# AT32F457xx_v2 register map
Vendor: Keil; Series: AT32F457; File version: 1.0
CPU: CM4 r0p1, little endian, no MPU, FPU, 4 interrupt priority bits
Registers are 32-bit, read-write, reset 0x0 unless marked. A register's access mark holds for its fields unless they carry their own. Offsets are from the block's base; [hi:lo] are bit positions; {n}, {i} and the like mark numbered series.

## CRM — Clock and reset management
Base 0x40023800
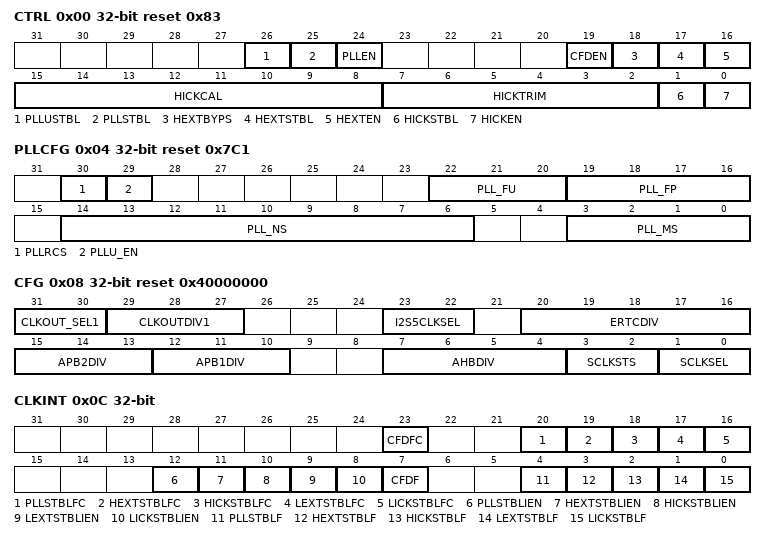
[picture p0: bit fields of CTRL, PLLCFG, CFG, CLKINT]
0x00 CTRL reset 0x83 — Clock control register
  [26] PLLUSTBL ro — PLLU clock ready flag
  [25] PLLSTBL ro — PLL clock ready flag
  [24] PLLEN — PLL enable
  [19] CFDEN — Clock failure detection enable
  [18] HEXTBYPS — High speed exernal crystal bypass
  [17] HEXTSTBL ro — High speed exernal crystal ready flag
  [16] HEXTEN — High speed exernal crystal enable
  [15:8] HICKCAL ro — High speed internal clock calibration
  [7:2] HICKTRIM — High speed internal clock trimming
  [1] HICKSTBL ro — High speed internal clock ready flag
  [0] HICKEN — High speed internal clock enable
0x04 PLLCFG reset 0x7C1 — PLL configuration register (CRM_PLLCFG)
  [30] PLLRCS — PLL reference clock select
  [29] PLLU_EN — PLLU enable
  [22:20] PLL_FU — PLLU post-division
  [19:16] PLL_FP — PLLP post-division
  [14:6] PLL_NS — PLL frequency multiplication factor
  [3:0] PLL_MS — PLL pre-division
0x08 CFG reset 0x40000000 — Clock configuration register(CRM_CFG)
  [31:30] CLKOUT_SEL1 — Clock output selection1
  [29:27] CLKOUTDIV1 — Clock output division1
  [23:22] I2S5CLKSEL — I2S clock select
  [20:16] ERTCDIV — HEXT division for ERTC clock
  [15:13] APB2DIV — APB2 division
  [12:10] APB1DIV — APB1 division
  [7:4] AHBDIV — AHB division
  [3:2] SCLKSTS ro — System Clock select Status
  [1:0] SCLKSEL — System clock select
0x0C CLKINT — Clock interrupt register (CRM_CLKINT)
  [23] CFDFC wo — Clock failure detection interrupt clear
  [20] PLLSTBLFC wo — PLL ready interrupt clear
  [19] HEXTSTBLFC wo — HEXT ready interrupt clear
  [18] HICKSTBLFC wo — HICK ready interrupt clear
  [17] LEXTSTBLFC wo — LEXT ready interrupt clear
  [16] LICKSTBLFC wo — LICK ready interrupt clear
  [12] PLLSTBLIEN — PLL ready interrupt enable
  [11] HEXTSTBLIEN — HEXT ready interrupt enable
  [10] HICKSTBLIEN — HICK ready interrupt enable
  [9] LEXTSTBLIEN — LEXT ready interrupt enable
  [8] LICKSTBLIEN — LICK ready interrupt enable
  [7] CFDF ro — Clock failure detection interrupt flag
  [4] PLLSTBLF ro — PLL ready interrupt flag
  [3] HEXTSTBLF ro — HEXT ready interrupt flag
  [2] HICKSTBLF ro — HICK ready interrupt flag
  [1] LEXTSTBLF ro — LEXT ready interrupt flag
  [0] LICKSTBLF ro — LICK ready interrupt flag
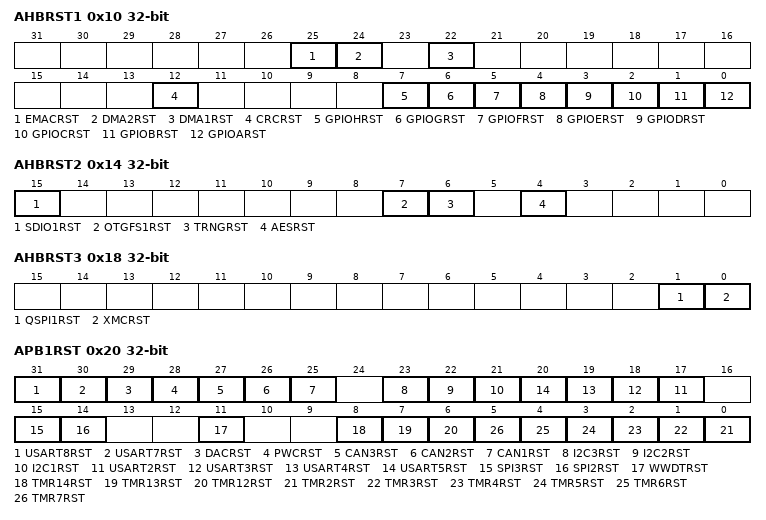
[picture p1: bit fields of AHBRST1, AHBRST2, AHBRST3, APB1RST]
0x10 AHBRST1 — AHB peripheral reset register1 (CRM_AHBRST1)
  [25] EMACRST — EMAC interface reset
  [24] DMA2RST — DMA2 reset
  [22] DMA1RST — DMA1 reset
  [12] CRCRST — CRC reset
  [7] GPIOHRST — IO port H reset
  [6] GPIOGRST — IO port G reset
  [5] GPIOFRST — IO port F reset
  [4] GPIOERST — IO port E reset
  [3] GPIODRST — IO port D reset
  [2] GPIOCRST — IO port C reset
  [1] GPIOBRST — IO port B reset
  [0] GPIOARST — IO port A reset
0x14 AHBRST2 — AHB peripheral reset register 2 (CRM_AHBRST2)
  [15] SDIO1RST — SDIO1 reset
  [7] OTGFS1RST — OTGFS1 reset
  [6] TRNGRST — TRNG reset
  [4] AESRST — AES reset
0x18 AHBRST3 — AHB peripheral reset register 3 (CRM_AHBRST3)
  [1] QSPI1RST — QSPI1 reset
  [0] XMCRST — XMC reset
0x20 APB1RST — APB1 peripheral reset register (CRM_APB1RST)
  [31] USART8RST — USART8 reset
  [30] USART7RST — USART7 reset
  [29] DACRST — DAC reset
  [28] PWCRST — PWC reset
  [27] CAN3RST — CAN3 reset
  [26] CAN2RST — CAN2 reset
  [25] CAN1RST — CAN1 reset
  [23] I2C3RST — I2C3 reset
  [22] I2C2RST — I2C2 reset
  [21] I2C1RST — I2C1 reset
  [n+15] USART{n}RST (n=2..5) — USART{n} reset
  [15] SPI3RST — SPI3 reset
  [14] SPI2RST — SPI2 reset
  [11] WWDTRST — Window watchdog reset
  [8] TMR14RST — Timer14 reset
  [7] TMR13RST — Timer13 reset
  [6] TMR12RST — Timer12 reset
  [n-2] TMR{n}RST (n=2..7) — Timer{n} reset
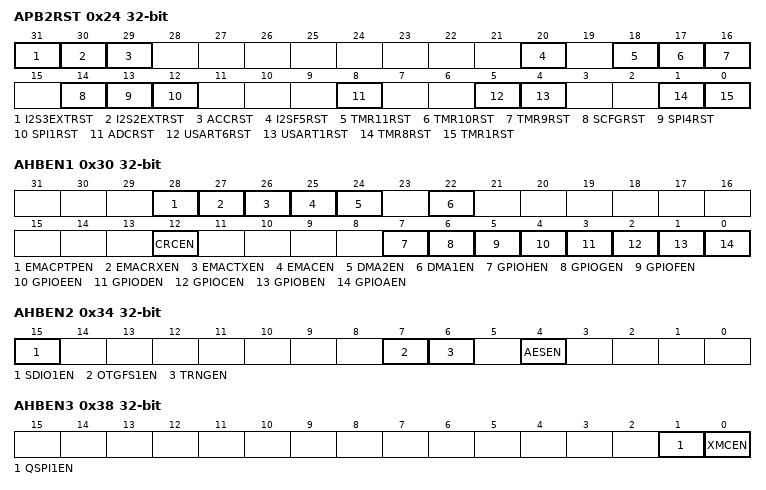
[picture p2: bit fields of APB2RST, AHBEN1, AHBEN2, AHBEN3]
0x24 APB2RST — APB2 peripheral reset register (CRM_APB2RST)
  [31] I2S3EXTRST — I2S3EXT reset
  [30] I2S2EXTRST — I2S2EXT reset
  [29] ACCRST — ACC reset
  [20] I2SF5RST — I2SF5 reset
  [18] TMR11RST — Timer 11 reset
  [17] TMR10RST — Timer10 reset
  [16] TMR9RST — Timer9 reset
  [14] SCFGRST — SCFG reset
  [13] SPI4RST — SPI4 reset
  [12] SPI1RST — SPI1 reset
  [8] ADCRST — ADC reset
  [5] USART6RST — USART6 reset
  [4] USART1RST — USART1 reset
  [1] TMR8RST — Timer8 reset
  [0] TMR1RST — Timer1 reset
0x30 AHBEN1 — AHB Peripheral Clock enable register 1 (CRM_AHBEN1)
  [28] EMACPTPEN — EMACPTP clock enable
  [27] EMACRXEN — EMACRX clock enable
  [26] EMACTXEN — EMACTX clock enable
  [25] EMACEN — EMAC clock enable
  [24] DMA2EN — DMA2 clock enable
  [22] DMA1EN — DMA1 clock enable
  [12] CRCEN — CRC clock enable
  [7] GPIOHEN — IO H clock enable
  [6] GPIOGEN — IO G clock enable
  [5] GPIOFEN — IO F clock enable
  [4] GPIOEEN — IO E clock enable
  [3] GPIODEN — IO D clock enable
  [2] GPIOCEN — IO C clock enable
  [1] GPIOBEN — IO B clock enable
  [0] GPIOAEN — IO A clock enable
0x34 AHBEN2 — AHB peripheral clock enable register 2 (CRM_AHBEN2)
  [15] SDIO1EN — SDIO1 clock enable
  [7] OTGFS1EN — OTGFS1 clock enable
  [6] TRNGEN — TRNG clock enable
  [4] AESEN — AES clock enable
0x38 AHBEN3 — AHB peripheral clock enable register 3 (CRM_AHBEN3)
  [1] QSPI1EN — QSPI1 clock enable
  [0] XMCEN — XMC clock enable
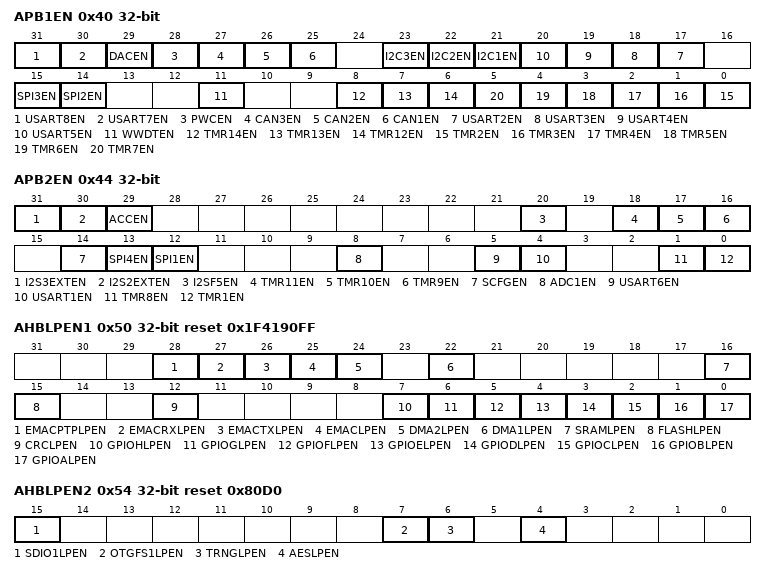
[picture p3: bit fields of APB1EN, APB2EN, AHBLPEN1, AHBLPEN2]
0x40 APB1EN — APB1 peripheral clock enable register (CRM_APB1EN)
  [31] USART8EN — USART8 clock enable
  [30] USART7EN — USART7 clock enable
  [29] DACEN — DAC clock enable
  [28] PWCEN — PWC clock enable
  [27] CAN3EN — CAN3 clock enable
  [26] CAN2EN — CAN2 clock enable
  [25] CAN1EN — CAN1 clock enable
  [23] I2C3EN — I2C3 clock enable
  [22] I2C2EN — I2C2 clock enable
  [21] I2C1EN — I2C1 clock enable
  [n+15] USART{n}EN (n=2..5) — USART{n} clock enable
  [15] SPI3EN — SPI3 clock enable
  [14] SPI2EN — SPI2 clock enable
  [11] WWDTEN — WWDT clock enable
  [8] TMR14EN — Timer14 clock enable
  [7] TMR13EN — Timer13 clock enable
  [6] TMR12EN — Timer12 clock enable
  [n-2] TMR{n}EN (n=2..7) — Timer{n} clock enable
0x44 APB2EN — APB2 peripheral clock enable register (CRM_APB2EN)
  [31] I2S3EXTEN — I2S3EXT clock enable
  [30] I2S2EXTEN — I2S2EXT clock enable
  [29] ACCEN — ACC clock enable
  [20] I2SF5EN — I2SF5 clock enable
  [18] TMR11EN — Timer11 clock enable
  [17] TMR10EN — Timer10 clock enable
  [16] TMR9EN — Timer9 clock enable
  [14] SCFGEN — SCFG clock enable
  [13] SPI4EN — SPI4 clock enable
  [12] SPI1EN — SPI1 clock enable
  [8] ADC1EN — ADC1 clock enable
  [5] USART6EN — USART6 clock enable
  [4] USART1EN — USART1 clock enable
  [1] TMR8EN — Timer8 clock enable
  [0] TMR1EN — Timer1 clock enable
0x50 AHBLPEN1 reset 0x1F4190FF — AHB Low-power Peripheral Clock enable register 1 (CRM_AHBLPEN1)
  [28] EMACPTPLPEN — EMACPTP clock enable during sleep mode
  [27] EMACRXLPEN — EMACRX clock enable during sleep mode
  [26] EMACTXLPEN — EMACTX clock enable during sleep mode
  [25] EMACLPEN — EMAC clock enable during sleep mode
  [24] DMA2LPEN — DMA2 clock enable during sleep mode
  [22] DMA1LPEN — DMA1 clock enable during sleep mode
  [16] SRAMLPEN — SRAM clock enable during sleep mode
  [15] FLASHLPEN — Flash clock enable during sleep mode
  [12] CRCLPEN — CRC clock enable during sleep mode
  [7] GPIOHLPEN — IO H clock enable during sleep mode
  [6] GPIOGLPEN — IO G clock enable during sleep mode
  [5] GPIOFLPEN — IO F clock enable during sleep mode
  [4] GPIOELPEN — IO E clock enable during sleep mode
  [3] GPIODLPEN — IO D clock enable during sleep mode
  [2] GPIOCLPEN — IO C clock enable during sleep mode
  [1] GPIOBLPEN — IO B clock enable during sleep mode
  [0] GPIOALPEN — IO A clock enable during sleep mode
0x54 AHBLPEN2 reset 0x80D0 — AHB peripheral Low-power clock enable register 2 (CRM_AHBLPEN2)
  [15] SDIO1LPEN — SDIO1 clock enable during sleep mode
  [7] OTGFS1LPEN — OTGFS1 clock enable during sleep mode
  [6] TRNGLPEN — TRNG clock enable during sleep mode
  [4] AESLPEN — AES clock enable during sleep mode
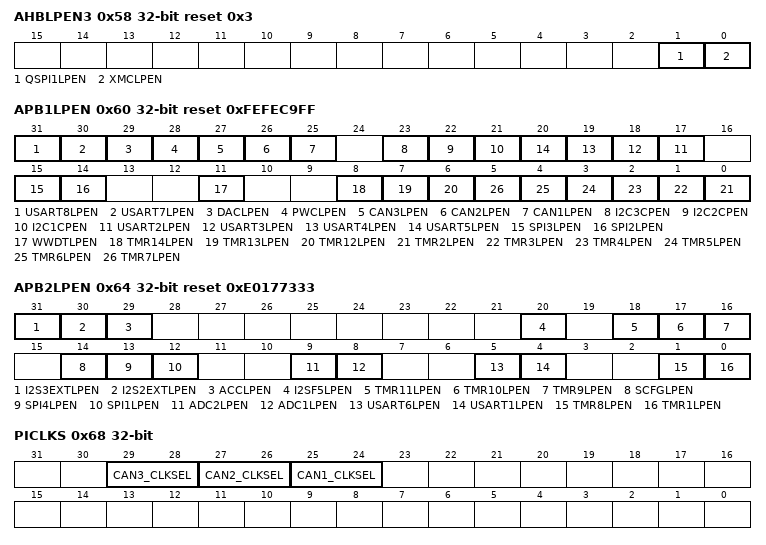
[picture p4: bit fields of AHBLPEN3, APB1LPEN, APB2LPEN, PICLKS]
0x58 AHBLPEN3 reset 0x3 — AHB peripheral Low-power clock enable register 3 (CRM_AHBLPEN3)
  [1] QSPI1LPEN — QSPI1 clock enable during sleep mode
  [0] XMCLPEN — XMC clock enable during sleep mode
0x60 APB1LPEN reset 0xFEFEC9FF — APB1 peripheral Low-power clock enable register (CRM_APB1LPEN)
  [31] USART8LPEN — USART8 clock enable during sleep mode
  [30] USART7LPEN — USART7 clock enable during sleep mode
  [29] DACLPEN — DAC clock enable during sleep mode
  [28] PWCLPEN — PWC clock enable during sleep mode
  [27] CAN3LPEN — CAN3 clock enable during sleep mode
  [26] CAN2LPEN — CAN2 clock enable during sleep mode
  [25] CAN1LPEN — CAN1 clock enable during sleep mode
  [23] I2C3CPEN — I2C3 clock enable during sleep mode
  [22] I2C2CPEN — I2C2 clock enable during sleep mode
  [21] I2C1CPEN — I2C1 clock enable during sleep mode
  [n+15] USART{n}LPEN (n=2..5) — USART{n} clock enable during sleep mode
  [15] SPI3LPEN — SPI3 clock enable during sleep mode
  [14] SPI2LPEN — SPI2 clock enable during sleep mode
  [11] WWDTLPEN — WWDT clock enable during sleep mode
  [8] TMR14LPEN — Timer14 clock enable during sleep mode
  [7] TMR13LPEN — Timer13 clock enable during sleep mode
  [6] TMR12LPEN — Timer12 clock enable during sleep mode
  [n-2] TMR{n}LPEN (n=2..7) — Timer{n} clock enable during sleep mode
0x64 APB2LPEN reset 0xE0177333 — APB2 peripheral Low-power clock enable register (CRM_APB2LPEN)
  [31] I2S3EXTLPEN — I2S3EXT clock enable during sleep mode
  [30] I2S2EXTLPEN — I2S2EXT clock enable during sleep mode
  [29] ACCLPEN — ACC clock enable during sleep mode
  [20] I2SF5LPEN — I2SF5 clock enable during sleep mode
  [18] TMR11LPEN — Timer11 clock enable during sleep mode
  [17] TMR10LPEN — Timer10 clock enable during sleep mode
  [16] TMR9LPEN — Timer9 clock enable during sleep mode
  [14] SCFGLPEN — SCFG clock enable during sleep mode
  [13] SPI4LPEN — SPI4 clock enable during sleep mode
  [12] SPI1LPEN — SPI1 clock enable during sleep mode
  [9] ADC2LPEN — ADC2 clock enable during sleep mode
  [8] ADC1LPEN — ADC1 clock enable during sleep mode
  [5] USART6LPEN — USART6 clock enable during sleep mode
  [4] USART1LPEN — USART1 clock enable during sleep mode
  [1] TMR8LPEN — Timer8 clock enable during sleep mode
  [0] TMR1LPEN — Timer1 clock enable during sleep mode
0x68 PICLKS — Peripheral independent clock config register (CRM_PICLKS)
  [29:28] CAN3_CLKSEL — CAN3 clock select
  [27:26] CAN2_CLKSEL — CAN2 clock select
  [25:24] CAN1_CLKSEL — CAN1 clock select
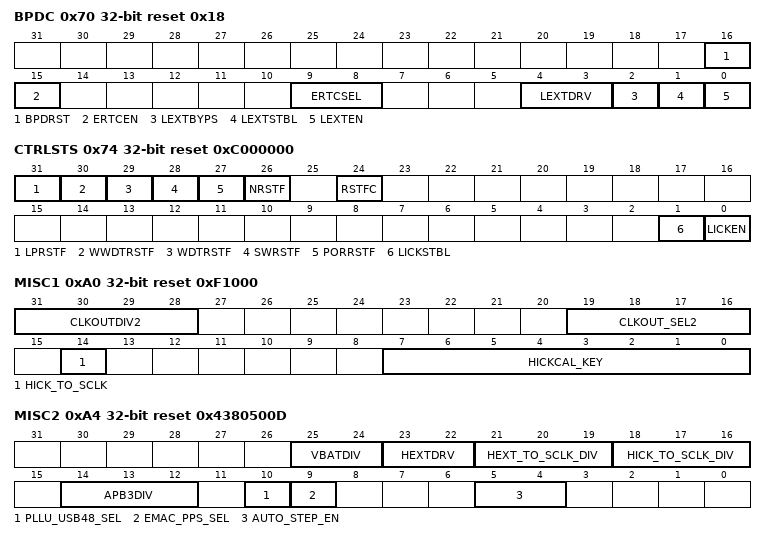
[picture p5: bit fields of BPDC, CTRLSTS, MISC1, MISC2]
0x70 BPDC reset 0x18 — Battery powered domain control register (CRM_BPDC)
  [16] BPDRST — Battery powered domain software reset
  [15] ERTCEN — ERTC clock enable
  [9:8] ERTCSEL — ERTC clock source selection
  [4:3] LEXTDRV — Low speed external crystal driving strength
  [2] LEXTBYPS — Low speed external crystal bypass
  [1] LEXTSTBL ro — Low speed external crystal ready
  [0] LEXTEN — Low speed external crystal enable
0x74 CTRLSTS reset 0xC000000 — Control/status register (CRM_CTRLSTS)
  [31] LPRSTF — Low-power reset flag
  [30] WWDTRSTF — Window watchdog timer reset flag
  [29] WDTRSTF — Watchdog timer reset flag
  [28] SWRSTF — Software reset flag
  [27] PORRSTF — POR/LVR reset flag
  [26] NRSTF — PIN reset flag
  [24] RSTFC — Reset reset flag
  [1] LICKSTBL ro — Low speed internal clock ready
  [0] LICKEN — Low speed internal clock enable
0xA0 MISC1 reset 0xF1000 — Miscellaneous register1
  [31:28] CLKOUTDIV2 — Clock output division2
  [19:16] CLKOUT_SEL2 — Clock output select2
  [14] HICK_TO_SCLK — HICK to system clock
  [7:0] HICKCAL_KEY — HICKCAL write key value
0xA4 MISC2 reset 0x4380500D — Miscellaneous register2
  [25:24] VBATDIV — VBAT AHB division
  [23:22] HEXTDRV — High speed external crystal driving strength
  [21:19] HEXT_TO_SCLK_DIV — HEXT as system clock frequency division
  [18:16] HICK_TO_SCLK_DIV — HICK as system clock frequency division
  [14:12] APB3DIV — APB3 division
  [10] PLLU_USB48_SEL — USB clock source select
  [9] EMAC_PPS_SEL — EMAC pulse select
  [5:4] AUTO_STEP_EN
